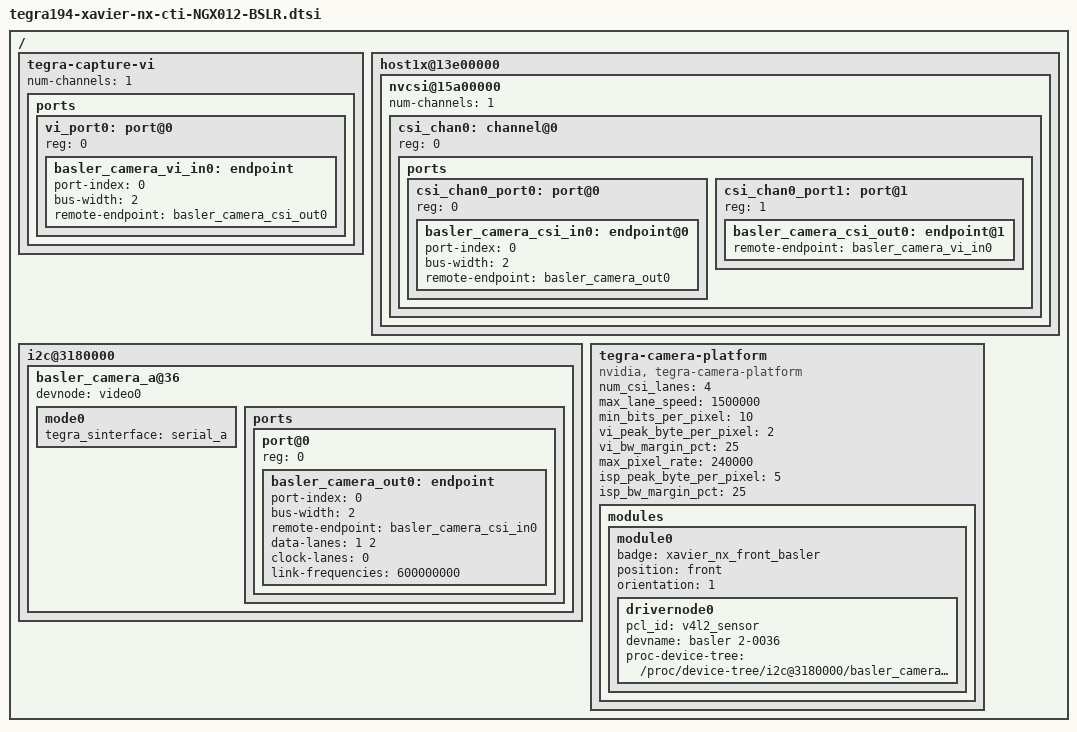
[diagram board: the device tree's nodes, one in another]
/*
 * Copyright (c) 2018-2019, NVIDIA CORPORATION.  All rights reserved.
 *
 * This program is free software; you can redistribute it and/or modify
 * it under the terms of the GNU General Public License as published by
 * the Free Software Foundation; either version 2 of the License, or
 * (at your option) any later version.
 *
 * This program is distributed in the hope that it will be useful, but WITHOUT
 * ANY WARRANTY; without even the implied warranty of MERCHANTABILITY or
 * FITNESS FOR A PARTICULAR PURPOSE.  See the GNU General Public License for
 * more details.
 *
 * You should have received a copy of the GNU General Public License
 * along with this program.  If not, see <http://www.gnu.org/licenses/>.
 */


/* camera control gpio definitions */
/*
 * Copyright (c) 2018-2019, NVIDIA CORPORATION.  All rights reserved.
 *
 * This program is free software; you can redistribute it and/or modify
 * it under the terms of the GNU General Public License as published by
 * the Free Software Foundation; either version 2 of the License, or
 * (at your option) any later version.
 *
 * This program is distributed in the hope that it will be useful, but WITHOUT
 * ANY WARRANTY; without even the implied warranty of MERCHANTABILITY or
 * FITNESS FOR A PARTICULAR PURPOSE.  See the GNU General Public License for
 * more details.
 *
 * You should have received a copy of the GNU General Public License
 * along with this program.  If not, see <http://www.gnu.org/licenses/>.
 */

#include <dt-bindings/media/camera.h>

#define SENSOR_COMMON   compatible = "basler,basler-camera"; \
                        physical_w = "3.680"; \
                        physical_h = "2.760"; \
                        reg = <0x36>; \
                        sensor_model = "basler-mcm";

/ {
		tegra-capture-vi {
			num-channels = <1>;
			status = "okay";
			ports {
				#address-cells = <1>;
				#size-cells = <0>;
				vi_port0: port@0 {
					status = "okay";
					reg = <0>;
					basler_camera_vi_in0: endpoint {
						status = "okay";
						port-index = <0>;
						bus-width = <2>;
						remote-endpoint = <&basler_camera_csi_out0>;
					};
				};

			};
		};

	host1x@13e00000 {
		nvcsi@15a00000 {
			num-channels = <1>;
			#address-cells = <1>;
			#size-cells = <0>;
			csi_chan0: channel@0 {
				status = "okay";
				reg = <0>;
				ports {
					#address-cells = <1>;
					#size-cells = <0>;
					csi_chan0_port0: port@0 {
						status = "okay";
						reg = <0>;
						basler_camera_csi_in0: endpoint@0 {
							status = "okay";
							port-index = <0>;
							bus-width = <2>;
							remote-endpoint = <&basler_camera_out0>;
						};
					};
					csi_chan0_port1: port@1 {
						status = "okay";
						reg = <1>;
						basler_camera_csi_out0: endpoint@1 {
							remote-endpoint = <&basler_camera_vi_in0>;
						};
					};
				};
			};

		};
	};

	i2c@3180000 {
			
			basler_camera_a@36 {
                SENSOR_COMMON
				devnode = "video0";
                status = "okay";

                mode0 {
                    tegra_sinterface = "serial_a";
                 }; 
						ports {
							#address-cells = <1>;
							#size-cells = <0>;

							port@0 {
								reg = <0>;
                                basler_camera_out0: endpoint {
                                    port-index = <0>;
                                    bus-width = <2>;
                                    remote-endpoint = <&basler_camera_csi_in0>;
                                    data-lanes = <1 2>;
                                    clock-lanes = <0>;
                                    link-frequencies = /bits/ 64 <600000000>;
                                };
							
                            };
						};
					};
		};
};

/ {
    tegra-camera-platform {
        compatible = "nvidia, tegra-camera-platform";

        /**
        * Physical settings to calculate max ISO BW
        *
        * num_csi_lanes = <>;
        * Total number of CSI lanes when all cameras are active
        *
        * max_lane_speed = <>;
        * Max lane speed in Kbit/s
        *
        * min_bits_per_pixel = <>;
        * Min bits per pixel
        *
        * vi_peak_byte_per_pixel = <>;
        * Max byte per pixel for the VI ISO case
        *
        * vi_bw_margin_pct = <>;
        * Vi bandwidth margin in percentage
        *
        * max_pixel_rate = <>;
        * Max pixel rate in Kpixel/s for the ISP ISO case
        *
        * isp_peak_byte_per_pixel = <>;
        * Max byte per pixel for the ISP ISO case
        *
        * isp_bw_margin_pct = <>;
        * Isp bandwidth margin in percentage
        */
        num_csi_lanes = <4>;
        max_lane_speed = <1500000>;
        min_bits_per_pixel = <10>;
        vi_peak_byte_per_pixel = <2>;
        vi_bw_margin_pct = <25>;
        max_pixel_rate = <240000>;
        isp_peak_byte_per_pixel = <5>;
        isp_bw_margin_pct = <25>;

        /**
         * The general guideline for naming badge_info contains 3 parts, and is as follows,
         * The first part is the camera_board_id for the module; if the module is in a FFD
         * platform, then use the platform name for this part.
         * The second part contains the position of the module, ex. "rear" or "front".
         * The third part contains the last 6 characters of a part number which is found
         * in the module's specsheet from the vendor.
         */
        modules {
            module0 {
                badge = "xavier_nx_front_basler";
                position = "front";
                orientation = "1";
                drivernode0 {
                    pcl_id = "v4l2_sensor";
                    devname = "basler 2-0036";
                    proc-device-tree = "/proc/device-tree/i2c@3180000/basler_camera_a@36";
                };
            };
         };
    };
};

